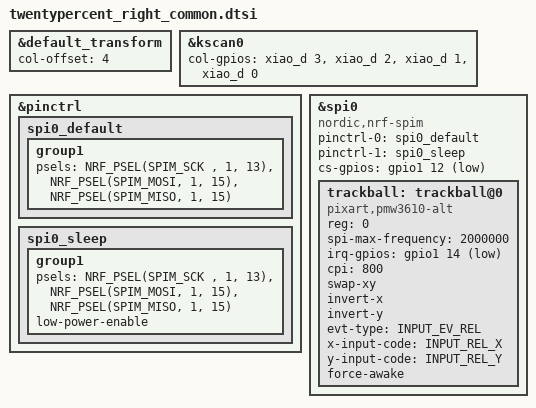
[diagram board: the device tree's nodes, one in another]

/*
 * Copyright (c) 2024 The ZMK Contributors
 * SPDX-License-Identifier: MIT
 *
 * Common hardware configuration for Charybdis right keyboard variants
 * Shared between charybdis_right_standalone and dongle_charybdis_right
 */

#include "twentypercent.dtsi"
#include <zephyr/dt-bindings/input/input-event-codes.h>

&default_transform {
	col-offset = <4>;
};

&kscan0{
  col-gpios
    = <&xiao_d 3 (GPIO_ACTIVE_HIGH | GPIO_PULL_DOWN)>
    , <&xiao_d 2 (GPIO_ACTIVE_HIGH | GPIO_PULL_DOWN)>
    , <&xiao_d 1 (GPIO_ACTIVE_HIGH | GPIO_PULL_DOWN)>
    , <&xiao_d 0 (GPIO_ACTIVE_HIGH | GPIO_PULL_DOWN)>
    ;
};

&pinctrl {
    spi0_default: spi0_default {
        group1 {
            psels =
                <NRF_PSEL(SPIM_SCK , 1, 13)>,
                <NRF_PSEL(SPIM_MOSI, 1, 15)>,
                <NRF_PSEL(SPIM_MISO, 1, 15)>;
        };
    };

    spi0_sleep: spi0_sleep {
        group1 {
            psels = 
                <NRF_PSEL(SPIM_SCK , 1, 13)>,
                <NRF_PSEL(SPIM_MOSI, 1, 15)>,
                <NRF_PSEL(SPIM_MISO, 1, 15)>;
            low-power-enable;
        };
    };
};

&spi0 {
    status = "okay";
    compatible = "nordic,nrf-spim";
    pinctrl-0 = <&spi0_default>;
    pinctrl-1 = <&spi0_sleep>;
    pinctrl-names = "default", "sleep";
    cs-gpios = <&gpio1 12 GPIO_ACTIVE_LOW>;

    trackball: trackball@0 {
        status = "okay";
        compatible = "pixart,pmw3610-alt";
        reg = <0>;
        spi-max-frequency = <2000000>;
        irq-gpios = <&gpio1 14 (GPIO_ACTIVE_LOW | GPIO_PULL_UP)>;
        cpi = <800>;
        swap-xy;
        invert-x;
        invert-y;
        evt-type = <INPUT_EV_REL>;
        x-input-code = <INPUT_REL_X>;
        y-input-code = <INPUT_REL_Y>;
        force-awake;
        /* keep the sensor awake while ZMK activity state is ACTIVE,
           fallback to normal downshift mode after ZMK goes into IDLE / SLEEP mode.
           thus, the sensor would be a `wakeup-source` */
        // force-awake-4ms-mode;
        /* while force-awake is acitvated, enable this mode to force sampling per
           4ms, where the default sampling rate is 8ms. */
        /* NOTE: apply this mode if you need 250Hz with direct USB connection. */
    };
};
